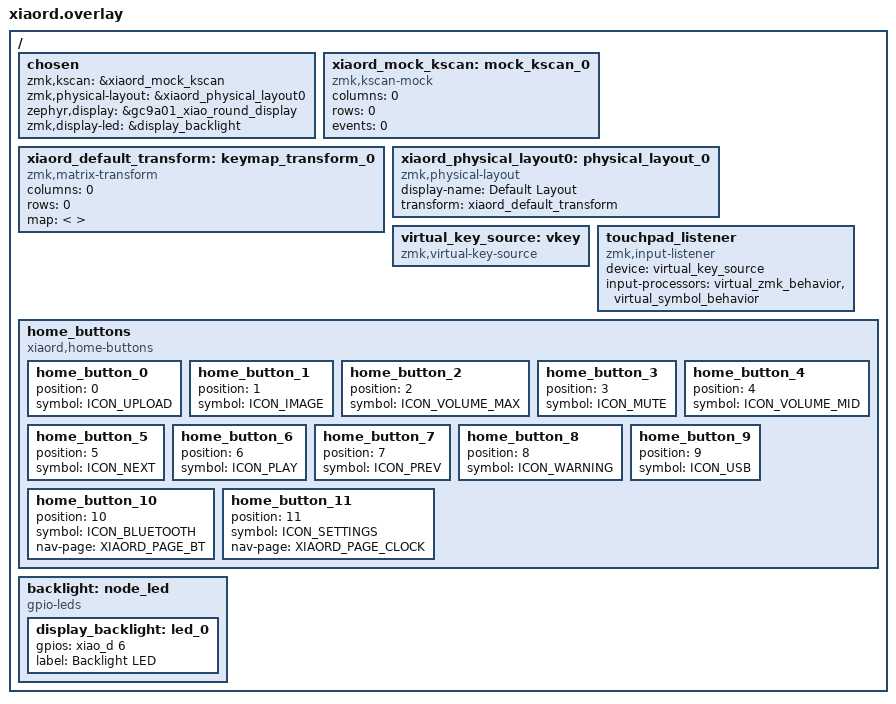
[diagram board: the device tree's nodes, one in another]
#include <../boards/shields/seeed_xiao_round_display/seeed_xiao_round_display.overlay>
#include <behaviors.dtsi>
#include <dt-bindings/zmk/keys.h>
#include <zephyr/dt-bindings/input/input-event-codes.h>
#include <dt-bindings/xiaord/input_codes.h>
#include <dt-bindings/xiaord/icons.h>
#include "zmk_behaviors.dtsi"

/ {
    chosen {
        zmk,kscan = &xiaord_mock_kscan;
        zmk,physical-layout = &xiaord_physical_layout0;
        zephyr,display = &gc9a01_xiao_round_display;
        zmk,display-led = &display_backlight;
    };

    xiaord_mock_kscan: mock_kscan_0 {
        compatible = "zmk,kscan-mock";
        columns = <0>;
        rows = <0>;
        events = <0>;
    };

    xiaord_default_transform: keymap_transform_0 {
        compatible = "zmk,matrix-transform";
        columns = <0>;
        rows = <0>;
        map = < >;
    };

    xiaord_physical_layout0: physical_layout_0 {
        compatible = "zmk,physical-layout";
        display-name = "Default Layout";
        transform = <&xiaord_default_transform>;
    };

    virtual_key_source: vkey {
        compatible = "zmk,virtual-key-source";
    };

    touchpad_listener: touchpad_listener {
        compatible = "zmk,input-listener";
        device = <&virtual_key_source>;
        input-processors = <&virtual_zmk_behavior &virtual_symbol_behavior>;
    };

    home_buttons {
        compatible = "xiaord,home-buttons";

        home_button_0: home_button_0 {
            position = <0>;  /* 12 o'clock */
            symbol = <ICON_UPLOAD>;
        };
        home_button_1: home_button_1 {
            position = <1>;  /* 1 o'clock */
            symbol = <ICON_IMAGE>;
        };
        home_button_2: home_button_2 {
            position = <2>;  /* 2 o'clock */
            symbol = <ICON_VOLUME_MAX>;
        };
        home_button_3: home_button_3 {
            position = <3>;  /* 3 o'clock */
            symbol = <ICON_MUTE>;
        };
        home_button_4: home_button_4 {
            position = <4>;  /* 4 o'clock */
            symbol = <ICON_VOLUME_MID>;
        };
        home_button_5: home_button_5 {
            position = <5>;  /* 5 o'clock */
            symbol = <ICON_NEXT>;
        };
        home_button_6: home_button_6 {
            position = <6>;  /* 6 o'clock */
            symbol = <ICON_PLAY>;
        };
        home_button_7: home_button_7 {
            position = <7>;  /* 7 o'clock */
            symbol = <ICON_PREV>;
        };
        home_button_8: home_button_8 {
            position = <8>;  /* 8 o'clock */
            symbol = <ICON_WARNING>;
        };
        home_button_9: home_button_9 {
            position = <9>;  /* 9 o'clock */
            symbol = <ICON_USB>;
        };
        home_button_10: home_button_10 {
            position = <10>; /* 10 o'clock */
            symbol = <ICON_BLUETOOTH>;
            nav-page = <XIAORD_PAGE_BT>;
        };
        home_button_11: home_button_11 {
            position = <11>; /* 11 o'clock */
            symbol = <ICON_SETTINGS>;
            nav-page = <XIAORD_PAGE_CLOCK>;
        };
    };

    backlight: node_led {
        compatible = "gpio-leds";
        display_backlight: led_0 {
            gpios = <&xiao_d 6 GPIO_ACTIVE_HIGH>;
            label = "Backlight LED";
        };
    };

};
